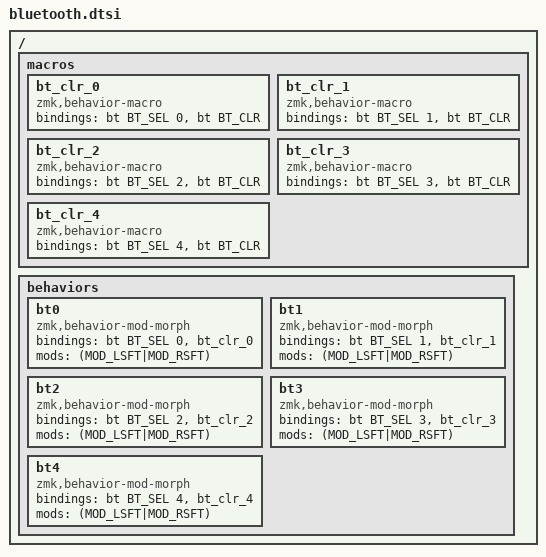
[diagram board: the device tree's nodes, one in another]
#include <behaviors.dtsi>
#include <dt-bindings/zmk/bt.h>
#include <dt-bindings/zmk/keys.h>

/ {
	macros {
        bt_clr_0: bt_clr_0 {
            compatible = "zmk,behavior-macro";
            #binding-cells = <0>;
            bindings = <&bt BT_SEL 0 &bt BT_CLR>;
        };

        bt_clr_1: bt_clr_1 {
            compatible = "zmk,behavior-macro";
            #binding-cells = <0>;
            bindings = <&bt BT_SEL 1 &bt BT_CLR>;
        };

        bt_clr_2: bt_clr_2 {
            compatible = "zmk,behavior-macro";
            #binding-cells = <0>;
            bindings = <&bt BT_SEL 2 &bt BT_CLR>;
        };

        bt_clr_3: bt_clr_3 {
            compatible = "zmk,behavior-macro";
            #binding-cells = <0>;
            bindings = <&bt BT_SEL 3 &bt BT_CLR>;
        };

        bt_clr_4: bt_clr_4 {
            compatible = "zmk,behavior-macro";
            #binding-cells = <0>;
            bindings = <&bt BT_SEL 4 &bt BT_CLR>;
        };
    };

    behaviors {
        bt0: bt0 {
            compatible = "zmk,behavior-mod-morph";
            bindings = <&bt BT_SEL 0>, <&bt_clr_0>;
            #binding-cells = <0>;
            mods = <(MOD_LSFT|MOD_RSFT)>;
        };

        bt1: bt1 {
            compatible = "zmk,behavior-mod-morph";
            bindings = <&bt BT_SEL 1>, <&bt_clr_1>;
            #binding-cells = <0>;
            mods = <(MOD_LSFT|MOD_RSFT)>;
        };

        bt2: bt2 {
            compatible = "zmk,behavior-mod-morph";
            bindings = <&bt BT_SEL 2>, <&bt_clr_2>;
            #binding-cells = <0>;
            mods = <(MOD_LSFT|MOD_RSFT)>;
        };

        bt3: bt3 {
            compatible = "zmk,behavior-mod-morph";
            bindings = <&bt BT_SEL 3>, <&bt_clr_3>;
            #binding-cells = <0>;
            mods = <(MOD_LSFT|MOD_RSFT)>;
        };

        bt4: bt4 {
            compatible = "zmk,behavior-mod-morph";
            bindings = <&bt BT_SEL 4>, <&bt_clr_4>;
            #binding-cells = <0>;
            mods = <(MOD_LSFT|MOD_RSFT)>;
        };
    };
};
